# hmac: IP-XACT component
VLNV tenstorrent.com:ocah:hmac:1.0

## Address spaces and blocks
hmac_mmap.hmac: base 'h0, range 'h2000, width 32

## Registers
Registers are 32-bit, read-write, no defined reset value unless marked. A register's access mark holds for its fields unless they carry their own. Offsets are from the block's base; lines under a group give offsets from that group; [hi:lo] are bit positions; {n}, {i} and the like mark numbered series; 'fields as' and 'values as' point back to an identical list; <NAME> marks a mode.

## hmac_mmap.hmac — Accelerator for SHA-2 256/384/512-based keyed HMAC and the hash function
Base 0x00000000
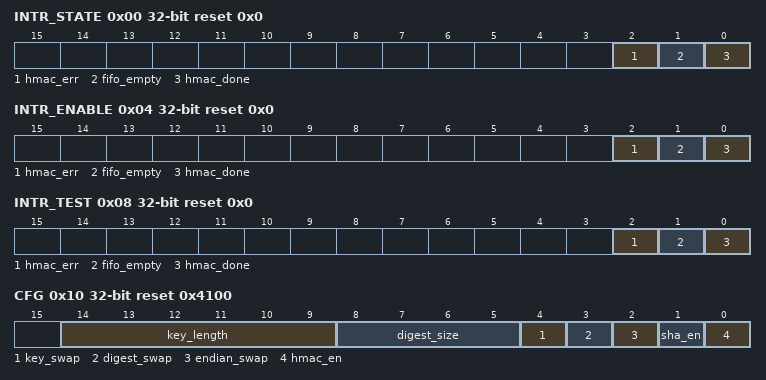
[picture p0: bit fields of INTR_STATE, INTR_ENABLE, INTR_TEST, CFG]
0x00 INTR_STATE access per field reset 0x0
  [2] hmac_err rw write-1-clears — HMAC error has occurred. ERR_CODE register shows which error occurred.
  [1] fifo_empty ro — The message FIFO is empty. This interrupt is raised only if the message FIFO is actually writable by software, i.e., if all of the following conditions are met: i) The HMAC block is not running in HMAC mode and performing the second round of computing the final hash of the outer key as well as the result of the first round using the inner key. ii) Software has not yet written the Process or Stop command to finish the hashing operation. For the interrupt to be raised, the message FIFO must also have been full previously. Otherwise, the hardware empties the FIFO faster than software can fill it and there is no point in interrupting the software to inform it about the message FIFO being empty.
  [0] hmac_done rw write-1-clears — HMAC/SHA-2 has completed.
0x04 INTR_ENABLE reset 0x0
  [2] hmac_err — Enable interrupt when !!INTR_STATE.hmac_err is set.
  [1] fifo_empty — Enable interrupt when !!INTR_STATE.fifo_empty is set.
  [0] hmac_done — Enable interrupt when !!INTR_STATE.hmac_done is set.
0x08 INTR_TEST wo reset 0x0
  [2] hmac_err — Write 1 to force !!INTR_STATE.hmac_err to 1.
  [1] fifo_empty — Write 1 to force !!INTR_STATE.fifo_empty to 1.
  [0] hmac_done — Write 1 to force !!INTR_STATE.hmac_done to 1.
0x0C ALERT_TEST wo reset 0x0
  [0] fatal_fault — Write 1 to trigger one alert event of this kind.
0x10 CFG reset 0x4100 (reset mask 0x7FFC)
  [14:9] key_length — Key length configuration. This is a 6-bit one-hot encoded field to configure the key length for HMAC. The HMAC can be programmed with the following key lengths: 128-bit, 256-bit, 384-bit, 512-bit and 1024-bit. But the HMAC supports any arbitrary key length: the software should configure the HMAC with the next largest supported key length and concatenate zeros to reach the programmed key length. The position of these zeros depends on the endianness, thus on the programmed [`CFG.key_swap`](registers.md#cfg--key_swap). For example, for an 80-bit key, HMAC should be configured with an 128-bit key length, fed with the 80-bit key and with 48 zero-bits. Note that the key length cannot be greater than the block size: up to 1024-bit for SHA-2 384/512 and up to 512-bit for SHA-2 256. The value of this register is irrelevant when only SHA-2 (not keyed HMAC) is configured. However, for HMAC mode (`hmac_en == 1`), when HMAC is triggered to start while !!KEY_LENGTH holds `Key_None` or !!KEY_LENGTH holds `Key_1024` for !!DIGEST_SIZE = `SHA2_256`, starting is blocked and an error is signalled to SW.
  [8:5] digest_size — Digest size configuration. This is a 4-bit one-hot encoded field to select digest size for either HMAC or SHA-2. Invalid/unsupported values, i.e., values that don't correspond to SHA2_256, SHA2_384, or SHA2_512, are mapped to SHA2_None.
  [4] key_swap — Key register byte swap (deprecated: KEY path is for DV only; production uses key manager sideload). If 1 the endianness of each KEY_* register is swapped. Default value (value 0) is big endian representation of the KEY_* CSRs.
  [3] digest_swap — Digest register byte swap. If 1 the value in each digest output register is converted to big-endian byte order. This setting does not affect the order of the digest output registers, !!DIGEST_0 still contains the first 4 bytes of the digest.
  [2] endian_swap — Endian swap. If 0, each value will be added to the message in little-endian byte order. The value is written to MSG_FIFO same to the SW writes. If 1, then each individual multi-byte value, regardless of its alignment, written to !!MSG_FIFO will be added to the message in big-endian byte order. A message written to !!MSG_FIFO one byte at a time will not be affected by this setting. From a hardware perspective byte swaps are performed on a TL-UL word granularity.
  [1] sha_en — SHA-2 enable. If 0, the SHA engine will not initiate compression, this is used to stop operation of the SHA-2 engine until configuration has been done. When the SHA-2 engine is disabled the digest is cleared.
  [0] hmac_en — HMAC datapath enable. If this bit is 1, HMAC operates when `hash_start` toggles.
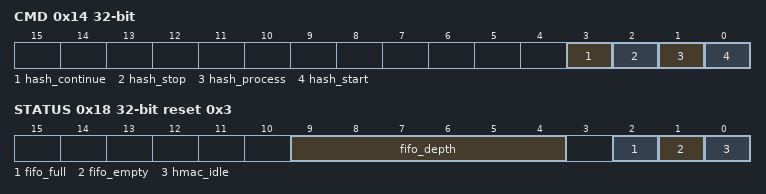
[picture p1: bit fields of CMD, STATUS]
0x14 CMD wo
  [3] hash_continue write-1-clears — When 1 is written to this field, SHA-2 or HMAC will continue hashing based on the current hash in the digest registers and the message length, which both have to be restored to switch context.
  [2] hash_stop write-1-clears — When 1 is written to this field, SHA-2 or HMAC will afterwards set the `hmac_done` interrupt as soon as the current block has been hashed. The hash can then be read from the registers !!DIGEST_0 to !!DIGEST_15. Together with the message length in !!MSG_LENGTH_LOWER and !!MSG_LENGTH_UPPER, this forms the information that has to be saved before switching context.
  [1] hash_process write-1-clears — If 1 is written to this field, SHA-2 or HMAC calculates the digest or signing based on currently received message.
  [0] hash_start write-1-clears — If 1 is written into this field, SHA-2 or HMAC begins its operation. CPU must configure relative information first, such as the digest size, secret key and the key length.
0x18 STATUS ro reset 0x3 (reset mask 0x3)
  [9:4] fifo_depth — FIFO entry count.
  [2] fifo_full — FIFO full. Data written to the FIFO whilst it is full will cause back-pressure on the interconnect
  [1] fifo_empty
  [0] hmac_idle — HMAC idle status. When IDLE, the `DIGEST` and the `MSG_LENGTH_LOWER`/`MSG_LENGTH_UPPER` can be written to from SW which enables restoring context (to support context switching).
0x1C ERR_CODE ro reset 0x0
  [31:0] err_code — If an error interrupt occurs, this register has information of error cause. Please take a look at `hw/ip/prim/rtl/prim_sha2_pkg.sv:err_code_e enum type.
0x20 WIPE_SECRET wo
  [31:0] secret — Secret value
{0x24+4i} KEY[{i}] (i=0..31) wo
  [31:0] key_0 — 32-bit chunk of 1024-bit secret key
{0xA4+4i} DIGEST[{i}] (i=0..15)
  [31:0] digest_0 — 32-bit chunk of 512-bit digest
0xE4 MSG_LENGTH_LOWER
  [31:0] v — Message Length [31:0]
0xE8 MSG_LENGTH_UPPER
  [31:0] v — Message Length [63:32]

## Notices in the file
SPDX-License-Identifier: Apache-2.0
SPDX-FileCopyrightText: 2026 Tenstorrent USA, Inc.
